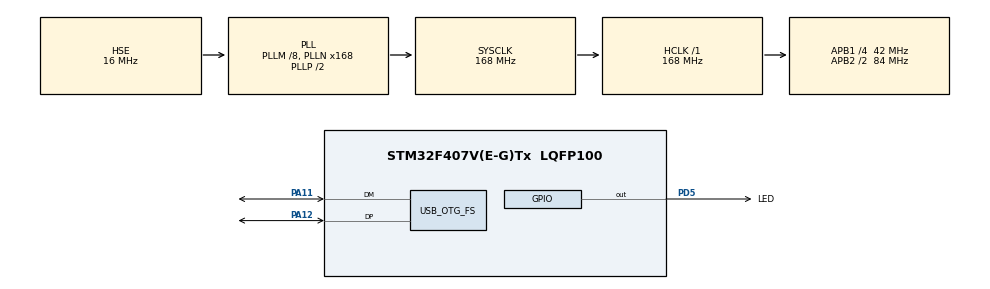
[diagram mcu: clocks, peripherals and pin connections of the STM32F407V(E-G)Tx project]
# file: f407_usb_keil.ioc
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FREERTOS.Mutexes01=USB_Mutex,Dynamic,NULL
FREERTOS.Queues01=USB_RX_Queue,512,uint8_t,0,Dynamic,NULL,NULL
FREERTOS.Tasks01=MainTask,24,256,StartMainTask,Default,NULL,Dynamic,NULL,NULL;USB_Task,24,128,StartUSBTask,Default,NULL,Dynamic,NULL,NULL;Parsing_Task,8,128,StartParsingTask,Default,NULL,Dynamic,NULL,NULL
Mcu.Family=STM32F4
Mcu.Name=STM32F407V(E-G)Tx
Mcu.Package=LQFP100
NVIC.OTG_FS_IRQn=true\:15\:0\:true\:false\:true\:false\:false\:true
NVIC.PriorityGroup=NVIC_PRIORITYGROUP_4
NVIC.TIM1_UP_TIM10_IRQn=true\:0\:0\:false\:false\:true\:false\:false\:true
NVIC.TimeBase=TIM1_UP_TIM10_IRQn
NVIC.TimeBaseIP=TIM1
PA11.Mode=Device_Only
PA11.Signal=USB_OTG_FS_DM
PA12.Mode=Device_Only
PA12.Signal=USB_OTG_FS_DP
PA13.Mode=Trace_Asynchronous_SW
PA13.Signal=SYS_JTMS-SWDIO
PA14.Mode=Trace_Asynchronous_SW
PA14.Signal=SYS_JTCK-SWCLK
PB3.Mode=Trace_Asynchronous_SW
PB3.Signal=SYS_JTDO-SWO
PD5.GPIO_Label=LED
PD5.Signal=GPIO_Output
PH0-OSC_IN.Mode=HSE-External-Oscillator
PH0-OSC_IN.Signal=RCC_OSC_IN
PH1-OSC_OUT.Mode=HSE-External-Oscillator
PH1-OSC_OUT.Signal=RCC_OSC_OUT
ProjectManager.HeapSize=0x00
ProjectManager.StackSize=0x800
ProjectManager.TargetToolchain=MDK-ARM V5.27
RCC.48MHZClocksFreq_Value=48000000
RCC.AHBFreq_Value=168000000
RCC.APB1CLKDivider=RCC_HCLK_DIV4
RCC.APB1Freq_Value=42000000
RCC.APB1TimFreq_Value=84000000
RCC.APB2CLKDivider=RCC_HCLK_DIV2
RCC.APB2Freq_Value=84000000
RCC.APB2TimFreq_Value=168000000
RCC.CortexFreq_Value=168000000
RCC.HCLKFreq_Value=168000000
RCC.HSE_VALUE=16000000
RCC.HSI_VALUE=16000000
RCC.LSE_VALUE=32768
RCC.PLLM=8
RCC.PLLN=168
RCC.PLLQ=7
RCC.SYSCLKFreq_VALUE=168000000
RCC.SYSCLKSource=RCC_SYSCLKSOURCE_PLLCLK
RCC.VCOOutputFreq_Value=336000000
USB_DEVICE.CLASS_NAME_FS=CDC
USB_DEVICE.VirtualMode-CDC_FS=Cdc
USB_DEVICE.VirtualModeFS=Cdc_FS
USB_OTG_FS.VirtualMode=Device_Only
VP_FREERTOS_VS_CMSIS_V2.Mode=CMSIS_V2
VP_SYS_VS_tim1.Mode=TIM1
VP_USB_DEVICE_VS_USB_DEVICE_CDC_FS.Mode=CDC_FS
board=custom

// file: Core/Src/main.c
/* USER CODE BEGIN Header */
/**
  ******************************************************************************
  * @file           : main.c
  * @brief          : Main program body
  ******************************************************************************
  * @attention
  *
  * <h2><center>&copy; Copyright (c) 2020 STMicroelectronics.
  * All rights reserved.</center></h2>
  *
  * This software component is licensed by ST under Ultimate Liberty license
  * SLA0044, the "License"; You may not use this file except in compliance with
  * the License. You may obtain a copy of the License at:
  *                             www.st.com/SLA0044
  *
  ******************************************************************************
  */
/* USER CODE END Header */
#include "main.h"
#include "cmsis_os.h"
#include "usb_device.h"

/* USER CODE BEGIN Includes */
#include "usbd_cdc_if.h"
/* USER CODE END Includes */

/* USER CODE BEGIN PTD */
#pragma import(__use_no_heap_region)
/* USER CODE END PTD */

/* USER CODE BEGIN PM */
uint8_t buffer[512];
uint32_t buffer_cnt;
/* USER CODE END PM */

/* Definitions for MainTask */
osThreadId_t MainTaskHandle;
const osThreadAttr_t MainTask_attributes = {
  .name = "MainTask",
  .priority = (osPriority_t) osPriorityNormal,
  .stack_size = 256 * 4
};
/* Definitions for USB_Task */
osThreadId_t USB_TaskHandle;
const osThreadAttr_t USB_Task_attributes = {
  .name = "USB_Task",
  .priority = (osPriority_t) osPriorityNormal,
  .stack_size = 128 * 4
};
/* Definitions for Parsing_Task */
osThreadId_t Parsing_TaskHandle;
const osThreadAttr_t Parsing_Task_attributes = {
  .name = "Parsing_Task",
  .priority = (osPriority_t) osPriorityLow,
  .stack_size = 128 * 4
};
/* Definitions for USB_RX_Queue */
osMessageQueueId_t USB_RX_QueueHandle;
const osMessageQueueAttr_t USB_RX_Queue_attributes = {
  .name = "USB_RX_Queue"
};
/* Definitions for USB_Mutex */
osMutexId_t USB_MutexHandle;
const osMutexAttr_t USB_Mutex_attributes = {
  .name = "USB_Mutex"
};

void SystemClock_Config(void);
static void MX_GPIO_Init(void);
void StartMainTask(void *argument);
void StartUSBTask(void *argument);
void StartParsingTask(void *argument);

int main(void)
{

  /* MCU Configuration--------------------------------------------------------*/

  /* Reset of all peripherals, Initializes the Flash interface and the Systick. */
  HAL_Init();

  /* Configure the system clock */
  SystemClock_Config();

  /* Initialize all configured peripherals */
  MX_GPIO_Init();

  /* Init scheduler */
  osKernelInitialize();
  /* Create the mutex(es) */
  /* creation of USB_Mutex */
  USB_MutexHandle = osMutexNew(&USB_Mutex_attributes);

  /* Create the queue(s) */
  /* creation of USB_RX_Queue */
  USB_RX_QueueHandle = osMessageQueueNew (512, sizeof(uint8_t), &USB_RX_Queue_attributes);

  /* Create the thread(s) */
  /* creation of MainTask */
  MainTaskHandle = osThreadNew(StartMainTask, NULL, &MainTask_attributes);

  /* creation of USB_Task */
  USB_TaskHandle = osThreadNew(StartUSBTask, NULL, &USB_Task_attributes);

  /* creation of Parsing_Task */
  Parsing_TaskHandle = osThreadNew(StartParsingTask, NULL, &Parsing_Task_attributes);

  /* Start scheduler */
  osKernelStart();

  /* We should never get here as control is now taken by the scheduler */
  /* Infinite loop */
  while (1)
  {

    /* USER CODE BEGIN 3 */

		HAL_Delay(10);

  }
  /* USER CODE END 3 */
}

void SystemClock_Config(void)
{
  RCC_OscInitTypeDef RCC_OscInitStruct = {0};
  RCC_ClkInitTypeDef RCC_ClkInitStruct = {0};

  /** Configure the main internal regulator output voltage
  */
  __HAL_RCC_PWR_CLK_ENABLE();
  __HAL_PWR_VOLTAGESCALING_CONFIG(PWR_REGULATOR_VOLTAGE_SCALE1);
  /** Initializes the RCC Oscillators according to the specified parameters
  * in the RCC_OscInitTypeDef structure.
  */
  RCC_OscInitStruct.OscillatorType = RCC_OSCILLATORTYPE_HSE;
  RCC_OscInitStruct.HSEState = RCC_HSE_ON;
  RCC_OscInitStruct.PLL.PLLState = RCC_PLL_ON;
  RCC_OscInitStruct.PLL.PLLSource = RCC_PLLSOURCE_HSE;
  RCC_OscInitStruct.PLL.PLLM = 8;
  RCC_OscInitStruct.PLL.PLLN = 168;
  RCC_OscInitStruct.PLL.PLLP = RCC_PLLP_DIV2;
  RCC_OscInitStruct.PLL.PLLQ = 7;
  if (HAL_RCC_OscConfig(&RCC_OscInitStruct) != HAL_OK)
  {
    Error_Handler();
  }
  /** Initializes the CPU, AHB and APB buses clocks
  */
  RCC_ClkInitStruct.ClockType = RCC_CLOCKTYPE_HCLK|RCC_CLOCKTYPE_SYSCLK
                              |RCC_CLOCKTYPE_PCLK1|RCC_CLOCKTYPE_PCLK2;
  RCC_ClkInitStruct.SYSCLKSource = RCC_SYSCLKSOURCE_PLLCLK;
  RCC_ClkInitStruct.AHBCLKDivider = RCC_SYSCLK_DIV1;
  RCC_ClkInitStruct.APB1CLKDivider = RCC_HCLK_DIV4;
  RCC_ClkInitStruct.APB2CLKDivider = RCC_HCLK_DIV2;

  if (HAL_RCC_ClockConfig(&RCC_ClkInitStruct, FLASH_LATENCY_5) != HAL_OK)
  {
    Error_Handler();
  }
}

static void MX_GPIO_Init(void)
{
  GPIO_InitTypeDef GPIO_InitStruct = {0};

  /* GPIO Ports Clock Enable */
  __HAL_RCC_GPIOH_CLK_ENABLE();
  __HAL_RCC_GPIOA_CLK_ENABLE();
  __HAL_RCC_GPIOD_CLK_ENABLE();
  __HAL_RCC_GPIOB_CLK_ENABLE();

  /*Configure GPIO pin Output Level */
  HAL_GPIO_WritePin(LED_GPIO_Port, LED_Pin, GPIO_PIN_RESET);

  /*Configure GPIO pin : LED_Pin */
  GPIO_InitStruct.Pin = LED_Pin;
  GPIO_InitStruct.Mode = GPIO_MODE_OUTPUT_PP;
  GPIO_InitStruct.Pull = GPIO_NOPULL;
  GPIO_InitStruct.Speed = GPIO_SPEED_FREQ_LOW;
  HAL_GPIO_Init(LED_GPIO_Port, &GPIO_InitStruct);

}

void StartMainTask(void *argument)
{
  /* init code for USB_DEVICE */
  MX_USB_DEVICE_Init();
  /* USER CODE BEGIN 5 */
  /* Infinite loop */
  for(;;)
  {
		HAL_GPIO_TogglePin(LED_GPIO_Port, LED_Pin);
    osDelay(100);
  }
  /* USER CODE END 5 */
}

void StartUSBTask(void *argument)
{
  /* USER CODE BEGIN StartUSBTask */
	uint8_t msg;
	osThreadId_t owner;

  /* Infinite loop */
  for(;;)
  {
		owner = osMutexGetOwner(USB_MutexHandle);
		if (owner != USB_TaskHandle) {
			osMutexAcquire(USB_MutexHandle, osWaitForever);
		}
		if (osMessageQueueGet(USB_RX_QueueHandle, &msg, 0, osWaitForever) == osOK) {
			buffer[buffer_cnt] = msg;
			buffer_cnt++;
			if (buffer[buffer_cnt - 1] == '\n') {
				if (buffer[buffer_cnt - 2] == '\r') {
					osMutexRelease(USB_MutexHandle);
					//osDelay(100);
				}
			}
		}
    osDelay(1);
  }
  /* USER CODE END StartUSBTask */
}

void StartParsingTask(void *argument)
{
  /* USER CODE BEGIN StartParsingTask */
	char *ptr;
	char cmd_buf[64];
	char send_buf[128];
  /* Infinite loop */
  for(;;)
  {
		osMutexAcquire(USB_MutexHandle, osWaitForever);
		ptr = strstr((char *)buffer, "echo");
		if (ptr != NULL) {
			sscanf((char *)buffer, "echo %63[^\r]\r\n", cmd_buf);
			snprintf(send_buf, sizeof(send_buf), "%s\r\n", cmd_buf);
			CDC_Transmit_FS((uint8_t *)send_buf, strlen(send_buf));
			memset(buffer, 0, buffer_cnt);
			buffer_cnt = 0;
		}
		osMutexRelease(USB_MutexHandle);
    osDelay(1);
  }
  /* USER CODE END StartParsingTask */
}

void HAL_TIM_PeriodElapsedCallback(TIM_HandleTypeDef *htim)
{
  if (htim->Instance == TIM1) {
    HAL_IncTick();
  }
}

void Error_Handler(void)
{
}

/************************ (C) COPYRIGHT STMicroelectronics *****END OF FILE****/
